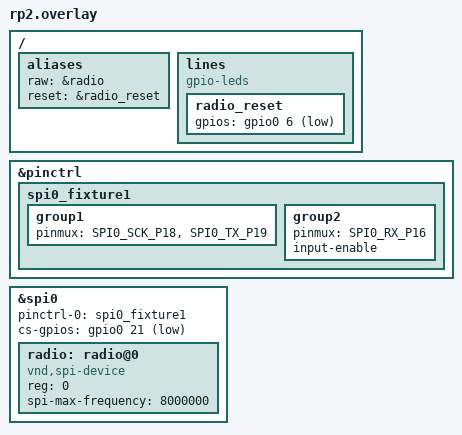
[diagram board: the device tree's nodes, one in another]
/* SPDX-License-Identifier: Apache-2.0 OR MIT */

#include <zephyr/dt-bindings/gpio/gpio.h>

/ {
	aliases {
		raw = &radio;
		reset = &radio_reset;
	};

	lines {
		compatible = "gpio-leds";

		radio_reset: radio_reset {
			gpios = <&gpio0 6 GPIO_ACTIVE_LOW>;
		};
	};
};

&pinctrl {
	spi0_fixture1: spi0_fixture1 {
		group1 {
			pinmux = <SPI0_SCK_P18>, <SPI0_TX_P19>;
		};
		group2 {
			pinmux = <SPI0_RX_P16>;
			input-enable;
		};
	};
};

/*
 * The radio as a bare SPI device: the cases clock its command frames
 * themselves through RAW, to check framing, status bytes and command
 * errors byte for byte and to qualify the clock, and pulse its NRESET on
 * GP6 through PULSE.
 */
&spi0 {
	status = "okay";
	pinctrl-0 = <&spi0_fixture1>;
	pinctrl-names = "default";
	cs-gpios = <&gpio0 21 GPIO_ACTIVE_LOW>;

	radio: radio@0 {
		compatible = "vnd,spi-device";
		reg = <0>;
		spi-max-frequency = <8000000>;
		status = "okay";
	};
};
